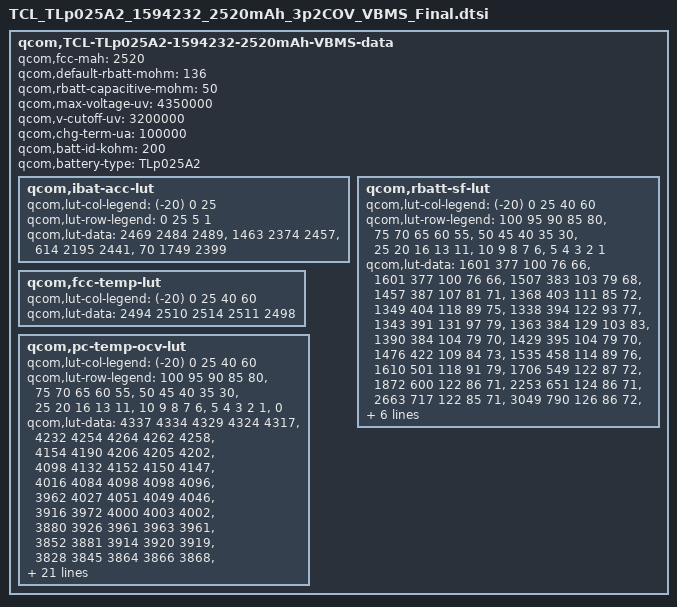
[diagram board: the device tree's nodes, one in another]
 qcom,TCL-TLp025A2-1594232-2520mAh-VBMS-data {
	qcom,fcc-mah = <2520>;
	qcom,default-rbatt-mohm = <136>;
	qcom,rbatt-capacitive-mohm = <50>;
	qcom,max-voltage-uv = <4350000>;
	qcom,v-cutoff-uv = <3200000>;
	qcom,chg-term-ua = <100000>;
	qcom,batt-id-kohm = <200>;
    qcom,battery-type = "TLp025A2";

	qcom,ibat-acc-lut {
		qcom,lut-col-legend = <(-20) 0 25>;
		qcom,lut-row-legend = <0 25 5 1>;
		qcom,lut-data = <2469 2484 2489>,
				<1463 2374 2457>,
				<614 2195 2441>,
				<70 1749 2399>;
	};

	qcom,rbatt-sf-lut {
		qcom,lut-col-legend = <(-20) 0 25 40 60>;
		qcom,lut-row-legend = <100 95 90 85 80>,
				<75 70 65 60 55>,
				<50 45 40 35 30>,
				<25 20 16 13 11>,
				<10 9 8 7 6>,
				<5 4 3 2 1>;
		qcom,lut-data = <1601 377 100 76 66>,
				<1601 377 100 76 66>,
				<1507 383 103 79 68>,
				<1457 387 107 81 71>,
				<1368 403 111 85 72>,
				<1349 404 118 89 75>,
				<1338 394 122 93 77>,
				<1343 391 131 97 79>,
				<1363 384 129 103 83>,
				<1390 384 104 79 70>,
				<1429 395 104 79 70>,
				<1476 422 109 84 73>,
				<1535 458 114 89 76>,
				<1610 501 118 91 79>,
				<1706 549 122 87 72>,
				<1872 600 122 86 71>,
				<2253 651 124 86 71>,
				<2663 717 122 85 71>,
				<3049 790 126 86 72>,
				<3312 845 137 90 74>,
				<3334 851 142 93 75>,
				<3281 862 146 95 75>,
				<3461 903 152 96 75>,
				<3844 947 156 97 74>,
				<4340 990 154 94 74>,
				<4999 1038 159 96 75>,
				<5903 1082 171 101 80>,
				<7314 1132 191 111 90>,
				<9906 1218 238 135 103>,
				<16762 2132 404 189 125>;
	};

	qcom,fcc-temp-lut {
		qcom,lut-col-legend = <(-20) 0 25 40 60>;
		qcom,lut-data = <2494 2510 2514 2511 2498>;
	};

	qcom,pc-temp-ocv-lut {
		qcom,lut-col-legend = <(-20) 0 25 40 60>;
		qcom,lut-row-legend = <100 95 90 85 80>,
				<75 70 65 60 55>,
				<50 45 40 35 30>,
				<25 20 16 13 11>,
				<10 9 8 7 6>,
				<5 4 3 2 1>,
				<0>;
		qcom,lut-data = <4337 4334 4329 4324 4317>,
				<4232 4254 4264 4262 4258>,
				<4154 4190 4206 4205 4202>,
				<4098 4132 4152 4150 4147>,
				<4016 4084 4098 4098 4096>,
				<3962 4027 4051 4049 4046>,
				<3916 3972 4000 4003 4002>,
				<3880 3926 3961 3963 3961>,
				<3852 3881 3914 3920 3919>,
				<3828 3845 3864 3866 3868>,
				<3808 3818 3836 3838 3838>,
				<3790 3800 3814 3816 3816>,
				<3774 3787 3795 3796 3796>,
				<3758 3776 3779 3780 3780>,
				<3744 3764 3768 3763 3754>,
				<3728 3749 3753 3746 3732>,
				<3711 3724 3728 3722 3710>,
				<3692 3704 3696 3690 3678>,
				<3674 3692 3684 3678 3666>,
				<3657 3684 3680 3675 3664>,
				<3648 3680 3679 3674 3662>,
				<3640 3674 3676 3672 3660>,
				<3628 3668 3672 3668 3656>,
				<3614 3656 3660 3658 3645>,
				<3594 3636 3632 3632 3617>,
				<3568 3604 3587 3590 3576>,
				<3530 3558 3530 3536 3524>,
				<3473 3494 3456 3470 3462>,
				<3390 3412 3366 3386 3380>,
				<3266 3276 3242 3256 3256>,
				<3000 3000 3000 3000 3000>;
	};
};
